# STM32WB05 register map
File version: 1.0
Registers are 32-bit, read-write, reset 0x0 unless marked. A register's access mark holds for its fields unless they carry their own. Offsets are from the block's base; [hi:lo] are bit positions; {n}, {i} and the like mark numbered series.

## IWDG
Base 0x40003000
0x00 KR
  [15:0] KEY
0x04 PR
  [2:0] PR
0x08 RLR
  [11:0] RL
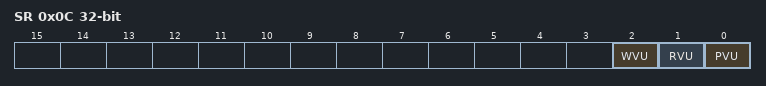
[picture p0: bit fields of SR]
0x0C SR
  [2] WVU, [1] RVU, [0] PVU
0x10 WINR
  [11:0] WIN

## RTC
Base 0x40004000
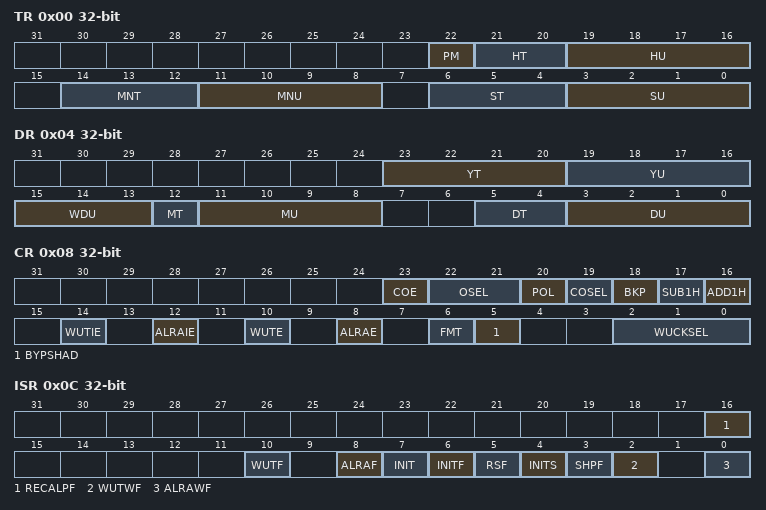
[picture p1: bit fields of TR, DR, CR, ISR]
0x00 TR
  [22] PM
    0=AM_OR_24 (AM or 24-hour format); 1=PM
  [21:20] HT
  [19:16] HU
  [14:12] MNT
  [11:8] MNU
  [6:4] ST
  [3:0] SU
0x04 DR
  [23:20] YT, [19:16] YU, [15:13] WDU, [12] MT, [11:8] MU, [5:4] DT, [3:0] DU
0x08 CR
  [23] COE
  [22:21] OSEL
    0=DISABLE (Output disabled); 1=ALMA (Alarm A output enabled); 2=ALMB (Alarm B output enabled); 3=WAKEUP (Wakeup output enabled)
  [20] POL
    0=HIGH (Pin is high when ALRAF/ALRBF/WUTF is asserted (depending on OSEL)); 1=LOW (Pin is low when ALRAF/ALRBF/WUTF is asserted (depending on OSEL))
  [19] COSEL
  [18] BKP
  [17] SUB1H
  [16] ADD1H
  [14] WUTIE
  [12] ALRAIE
  [10] WUTE
  [8] ALRAE
  [6] FMT
    0=HOURFORMAT_24HOUR (24 hour/day format); 1=AMPM (AM/PM hour format)
  [5] BYPSHAD
  [2:0] WUCKSEL
    0=DIV_16 (RTC/16 clock is selected); 1=DIV_8 (RTC/8 clock is selected); 2=DIV_4 (RTC/4 clock is selected); 3=DIV_2 (RTC/2 clock is selected); 4=CKSPRE (ck_spre (usually 1 Hz) clock is selected); 6=CKSPRE_WUT (ck_spre (usually 1 Hz) clock is selected and 2exp16 is added to the WUT counter value)
0x0C ISR
  [16] RECALPF, [10] WUTF, [8] ALRAF, [7] INIT, [6] INITF, [5] RSF, [4] INITS, [3] SHPF, [2] WUTWF, [0] ALRAWF
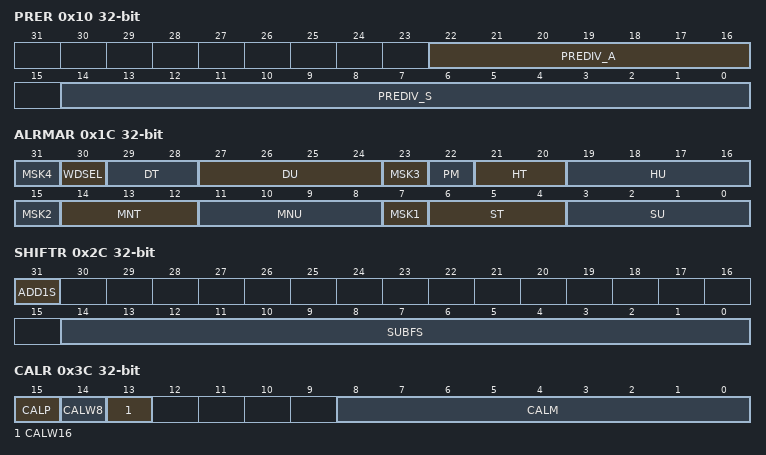
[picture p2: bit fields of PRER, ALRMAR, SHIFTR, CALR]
0x10 PRER
  [22:16] PREDIV_A, [14:0] PREDIV_S
0x14 WUTR
  [15:0] WUT
0x1C ALRMAR
  [8n-1] MSK{n} (n=1..4)
  [30] WDSEL
  [29:28] DT
  [27:24] DU
  [22] PM
    0=AM (AM or 24-hour format); 1=PM
  [21:20] HT
  [19:16] HU
  [14:12] MNT
  [11:8] MNU
  [6:4] ST
  [3:0] SU
0x24 WPR
  [7:0] KEY
0x28 SSR
  [15:0] SS
0x2C SHIFTR
  [31] ADD1S, [14:0] SUBFS
0x3C CALR
  [15] CALP
    0=NONE (No RTCCLK pulses are added); 1=SET (One RTCCLK pulse is effectively inserted every 2exp11 pulses (frequency increased by 488.5 ppm))
  [14] CALW8
  [13] CALW16
  [8:0] CALM
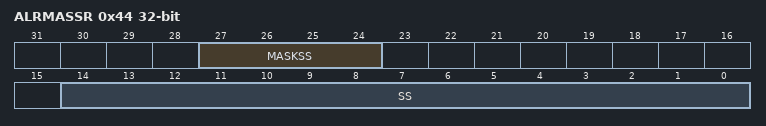
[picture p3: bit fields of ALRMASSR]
0x44 ALRMASSR
  [27:24] MASKSS, [14:0] SS
0x50 BKP0R
  [31:0] BKP
0x54 BKP1R
  [31:0] BKP

## TIM16
Base 0x40005000
Same registers: TIM17 0x40006000
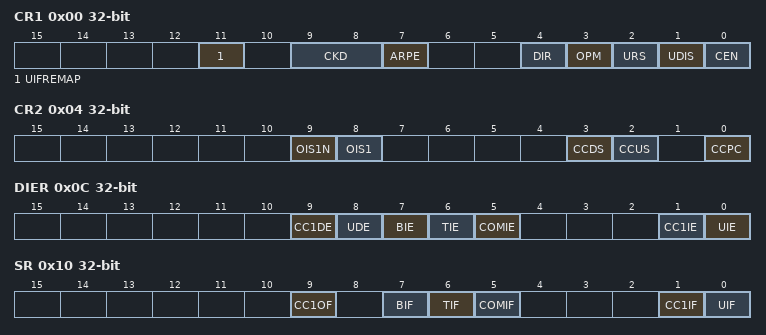
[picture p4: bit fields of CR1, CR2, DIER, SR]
0x00 CR1
  [11] UIFREMAP
  [9:8] CKD
    0=DIV1 (tDTS=tCK_INT); 1=DIV2 (tDTS=2*tCK_INT); 2=DIV4 (tDTS=4*tCK_INT)
  [7] ARPE
  [4] DIR
    0=UP (Timer counter counts up); 1=DOWN (Timer counter counts down)
  [3] OPM
    1=SINGLE (Counter stops counting at the next update event); 0=REPETITIVE (Counter is not stopped at update event)
  [2] URS
    0=REGULAR (Counter overflow/underflow, Setting the UG bit or Update generation through the slave mode controller generates an update request); 1=COUNTER (Only counter overflow/underflow generates an update request)
  [1] UDIS
  [0] CEN
0x04 CR2
  [9] OIS1N
  [8] OIS1
  [3] CCDS
    0=CC (CCx DMA request sent when CCx event occurs); 1=UPDATE (CCx DMA requests sent when update event occurs)
  [2] CCUS
    0=ONLY (Capture/compare control bits are updated by setting the COMG bit only); 1=AND_TRGI (Capture/compare control bits are updated by setting the COMG bit or when a rising edge occurs on trigger input (TRGI))
  [0] CCPC
0x08 SMCR
  [3] OCCS
    0=OCREF_CLR (OCREF_CLR_INT is connected to the OCREF_CLR input); 1=ETR (OCREF_CLR_INT is connected to ETRF)
0x0C DIER
  [9] CC1DE, [8] UDE, [7] BIE, [6] TIE, [5] COMIE, [1] CC1IE, [0] UIE
0x10 SR
  [9] CC1OF, [7] BIF, [6] TIF, [5] COMIF, [1] CC1IF, [0] UIF
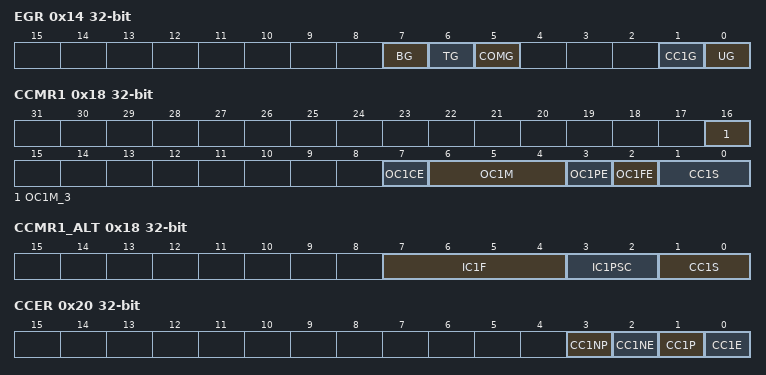
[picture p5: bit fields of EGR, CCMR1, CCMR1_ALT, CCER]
0x14 EGR
  [7] BG, [6] TG, [5] COMG, [1] CC1G, [0] UG
0x18 CCMR1
  [16] OC1M_3, [7] OC1CE, [6:4] OC1M, [3] OC1PE, [2] OC1FE, [1:0] CC1S
0x18 CCMR1_ALT (alternate view of CCMR1)
  [7:4] IC1F, [3:2] IC1PSC, [1:0] CC1S
0x20 CCER
  [3] CC1NP, [2] CC1NE, [1] CC1P, [0] CC1E
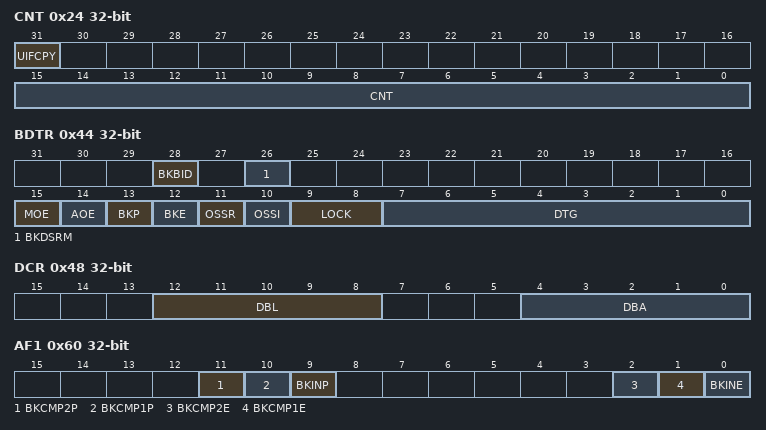
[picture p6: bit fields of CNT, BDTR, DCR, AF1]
0x24 CNT
  [31] UIFCPY, [15:0] CNT
0x28 PSC
  [15:0] PSC
0x2C ARR
  [15:0] ARR
0x30 RCR
  [7:0] REP
0x34 CCR1
  [15:0] CCR1
0x44 BDTR
  [28] BKBID
  [26] BKDSRM
  [15] MOE
  [14] AOE
  [13] BKP
  [12] BKE
  [11] OSSR
  [10] OSSI
  [9:8] LOCK
    0=OFF (LOCK OFF - No bit is write protected); 1=LOCKLEVEL_1; 2=LOCKLEVEL_2; 3=LOCKLEVEL_3
  [7:0] DTG
0x48 DCR
  [12:8] DBL, [4:0] DBA
0x4C DMAR
  [15:0] DMAB
0x50 OR1
  [1:0] TI1_RMP
0x60 AF1
  [11] BKCMP2P, [10] BKCMP1P, [9] BKINP, [2] BKCMP2E, [1] BKCMP1E, [0] BKINE
